dbc
VERSION ""

NS_ :

BS_:

BU_: Vector__XXX

BO_ 4096 TelemLeader_Center: 2 Vector__XXX
	SG_ Timestamp : 0|16@1+ (1,0) [0|65535] "" Vector__XXX
BA_ "VFrameFormat" BO_ 4096 "ExtendedCAN";

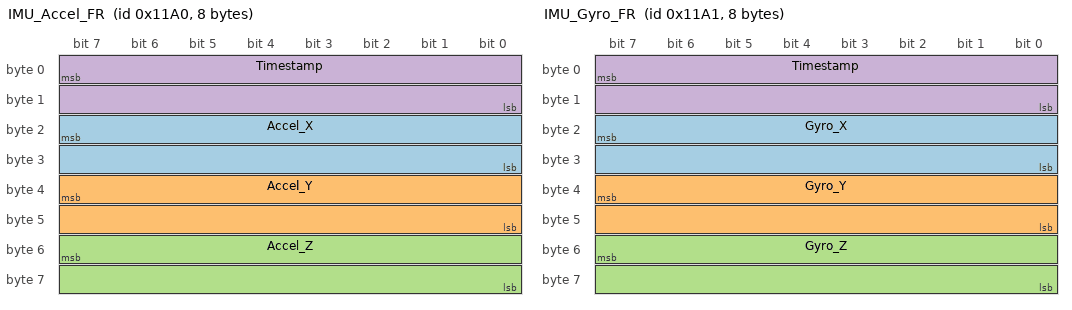
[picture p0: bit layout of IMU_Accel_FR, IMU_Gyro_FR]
BO_ 4512 IMU_Accel_FR: 8 Vector__XXX
	SG_ Accel_X : 23|16@0- (0.000122,0) [-3.997696|3.997574] "g" Vector__XXX
	SG_ Accel_Y : 39|16@0- (0.000122,0) [-3.997696|3.997574] "g" Vector__XXX
	SG_ Accel_Z : 55|16@0- (0.000122,0) [-3.997696|3.997574] "g" Vector__XXX
	SG_ Timestamp : 7|16@0+ (1,0) [0|65535] "" Vector__XXX
BA_ "VFrameFormat" BO_ 4512 "ExtendedCAN";

BO_ 4513 IMU_Gyro_FR: 8 Vector__XXX
	SG_ Gyro_X : 23|16@0- (0.00875,0) [-286.72|286.71125] "dps" Vector__XXX
	SG_ Gyro_Y : 39|16@0- (0.00875,0) [-286.72|286.71125] "dps" Vector__XXX
	SG_ Gyro_Z : 55|16@0- (0.00875,0) [-286.72|286.71125] "dps" Vector__XXX
	SG_ Timestamp : 7|16@0+ (1,0) [0|65535] "" Vector__XXX
BA_ "VFrameFormat" BO_ 4513 "ExtendedCAN";

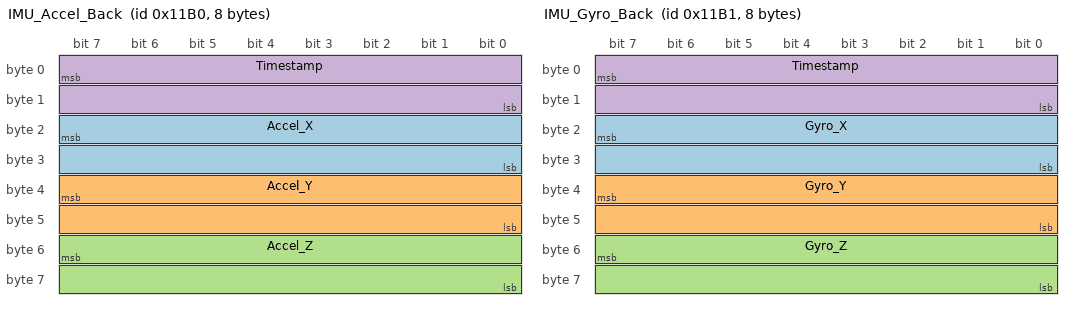
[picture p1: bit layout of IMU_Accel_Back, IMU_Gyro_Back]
BO_ 4528 IMU_Accel_Back: 8 Vector__XXX
	SG_ Accel_X : 23|16@0- (0.000122,0) [-3.997696|3.997574] "g" Vector__XXX
	SG_ Accel_Y : 39|16@0- (0.000122,0) [-3.997696|3.997574] "g" Vector__XXX
	SG_ Accel_Z : 55|16@0- (0.000122,0) [-3.997696|3.997574] "g" Vector__XXX
	SG_ Timestamp : 7|16@0+ (1,0) [0|65535] "" Vector__XXX
BA_ "VFrameFormat" BO_ 4528 "ExtendedCAN";

BO_ 4529 IMU_Gyro_Back: 8 Vector__XXX
	SG_ Gyro_X : 23|16@0- (0.00875,0) [-286.72|286.71125] "dps" Vector__XXX
	SG_ Gyro_Y : 39|16@0- (0.00875,0) [-286.72|286.71125] "dps" Vector__XXX
	SG_ Gyro_Z : 55|16@0- (0.00875,0) [-286.72|286.71125] "dps" Vector__XXX
	SG_ Timestamp : 7|16@0+ (1,0) [0|65535] "" Vector__XXX
BA_ "VFrameFormat" BO_ 4529 "ExtendedCAN";

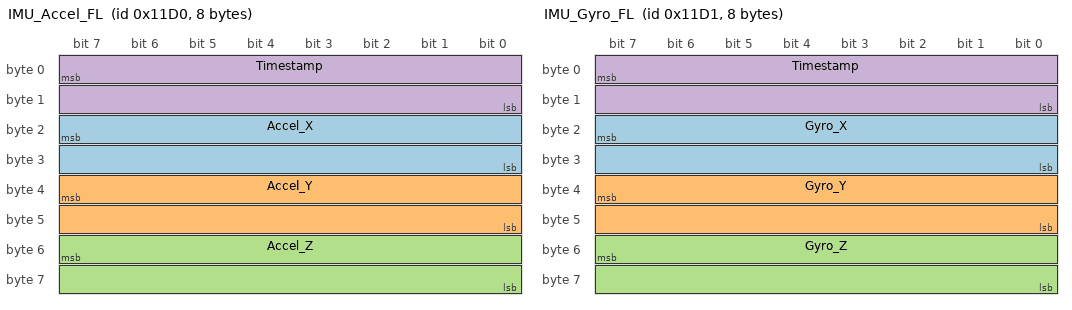
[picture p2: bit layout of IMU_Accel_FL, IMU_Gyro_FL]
BO_ 4560 IMU_Accel_FL: 8 Vector__XXX
	SG_ Accel_X : 23|16@0- (0.000122,0) [-3.997696|3.997574] "g" Vector__XXX
	SG_ Accel_Y : 39|16@0- (0.000122,0) [-3.997696|3.997574] "g" Vector__XXX
	SG_ Accel_Z : 55|16@0- (0.000122,0) [-3.997696|3.997574] "g" Vector__XXX
	SG_ Timestamp : 7|16@0+ (1,0) [0|65535] "" Vector__XXX
BA_ "VFrameFormat" BO_ 4560 "ExtendedCAN";

BO_ 4561 IMU_Gyro_FL: 8 Vector__XXX
	SG_ Gyro_X : 23|16@0- (0.00875,0) [-286.72|286.71125] "dps" Vector__XXX
	SG_ Gyro_Y : 39|16@0- (0.00875,0) [-286.72|286.71125] "dps" Vector__XXX
	SG_ Gyro_Z : 55|16@0- (0.00875,0) [-286.72|286.71125] "dps" Vector__XXX
	SG_ Timestamp : 7|16@0+ (1,0) [0|65535] "" Vector__XXX
BA_ "VFrameFormat" BO_ 4561 "ExtendedCAN";

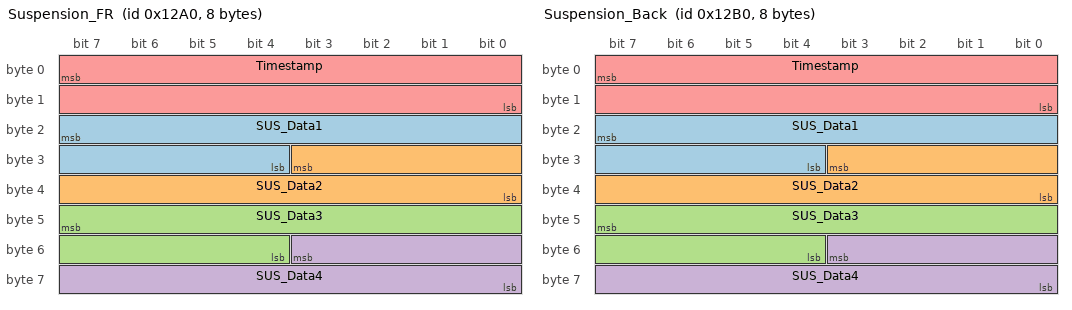
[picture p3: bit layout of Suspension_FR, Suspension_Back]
BO_ 4768 Suspension_FR: 8 Vector__XXX
	SG_ SUS_Data1 : 23|12@0+ (1,0) [0|4095] "" Vector__XXX
	SG_ SUS_Data2 : 27|12@0+ (1,0) [0|4095] "" Vector__XXX
	SG_ SUS_Data3 : 47|12@0+ (1,0) [0|4095] "" Vector__XXX
	SG_ SUS_Data4 : 51|12@0+ (1,0) [0|4095] "" Vector__XXX
	SG_ Timestamp : 7|16@0+ (1,0) [0|65535] "" Vector__XXX
BA_ "VFrameFormat" BO_ 4768 "ExtendedCAN";

BO_ 4784 Suspension_Back: 8 Vector__XXX
	SG_ SUS_Data1 : 23|12@0+ (1,0) [0|4095] "" Vector__XXX
	SG_ SUS_Data2 : 27|12@0+ (1,0) [0|4095] "" Vector__XXX
	SG_ SUS_Data3 : 47|12@0+ (1,0) [0|4095] "" Vector__XXX
	SG_ SUS_Data4 : 51|12@0+ (1,0) [0|4095] "" Vector__XXX
	SG_ Timestamp : 7|16@0+ (1,0) [0|65535] "" Vector__XXX
BA_ "VFrameFormat" BO_ 4784 "ExtendedCAN";

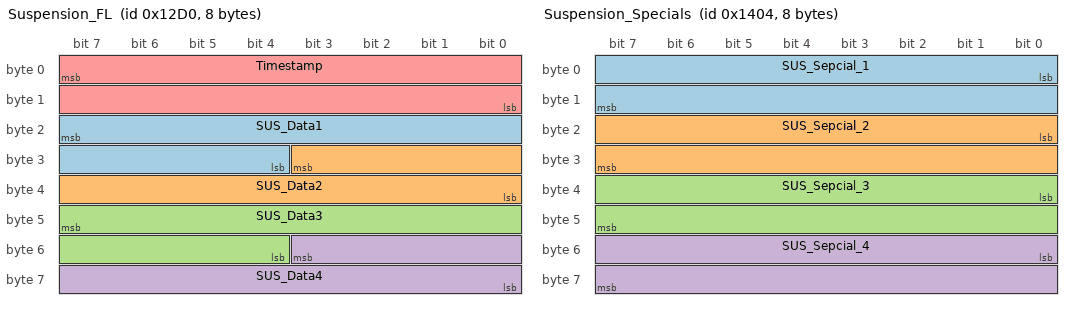
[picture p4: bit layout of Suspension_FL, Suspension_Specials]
BO_ 4816 Suspension_FL: 8 Vector__XXX
	SG_ SUS_Data1 : 23|12@0+ (1,0) [0|4095] "" Vector__XXX
	SG_ SUS_Data2 : 27|12@0+ (1,0) [0|4095] "" Vector__XXX
	SG_ SUS_Data3 : 47|12@0+ (1,0) [0|4095] "" Vector__XXX
	SG_ SUS_Data4 : 51|12@0+ (1,0) [0|4095] "" Vector__XXX
	SG_ Timestamp : 7|16@0+ (1,0) [0|65535] "" Vector__XXX
BA_ "VFrameFormat" BO_ 4816 "ExtendedCAN";

BO_ 5124 Suspension_Specials: 8 Vector__XXX
	SG_ SUS_Sepcial_1 : 0|16@1+ (1,0) [0|65535] "" Vector__XXX
	SG_ SUS_Sepcial_2 : 16|16@1+ (1,0) [0|65535] "" Vector__XXX
	SG_ SUS_Sepcial_3 : 32|16@1+ (1,0) [0|65535] "" Vector__XXX
	SG_ SUS_Sepcial_4 : 48|16@1+ (1,0) [0|65535] "" Vector__XXX
BA_ "VFrameFormat" BO_ 5124 "ExtendedCAN";

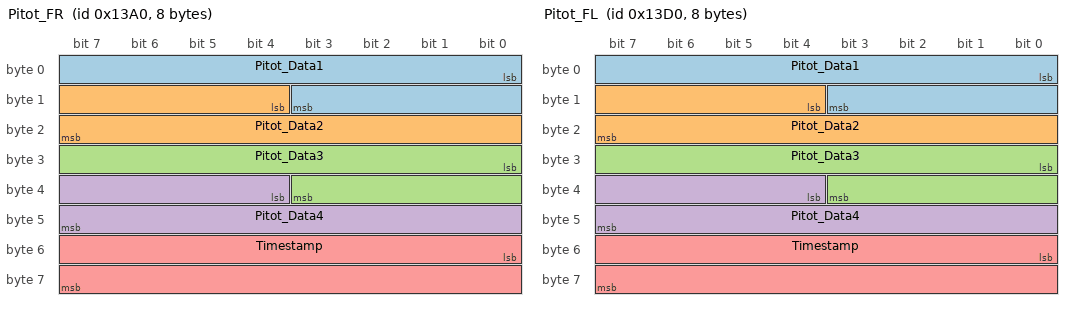
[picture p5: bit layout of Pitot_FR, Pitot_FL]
BO_ 5024 Pitot_FR: 8 Vector__XXX
	SG_ Pitot_Data1 : 0|12@1+ (1,0) [0|4095] "" Vector__XXX
	SG_ Pitot_Data2 : 12|12@1+ (1,0) [0|4095] "" Vector__XXX
	SG_ Pitot_Data3 : 24|12@1+ (1,0) [0|4095] "" Vector__XXX
	SG_ Pitot_Data4 : 36|12@1+ (1,0) [0|4095] "" Vector__XXX
	SG_ Timestamp : 48|16@1+ (1,0) [0|65535] "" Vector__XXX
BA_ "VFrameFormat" BO_ 5024 "ExtendedCAN";

BO_ 5072 Pitot_FL: 8 Vector__XXX
	SG_ Pitot_Data1 : 0|12@1+ (1,0) [0|4095] "" Vector__XXX
	SG_ Pitot_Data2 : 12|12@1+ (1,0) [0|4095] "" Vector__XXX
	SG_ Pitot_Data3 : 24|12@1+ (1,0) [0|4095] "" Vector__XXX
	SG_ Pitot_Data4 : 36|12@1+ (1,0) [0|4095] "" Vector__XXX
	SG_ Timestamp : 48|16@1+ (1,0) [0|65535] "" Vector__XXX
BA_ "VFrameFormat" BO_ 5072 "ExtendedCAN";

BO_ 5280 WheelRPM_FR: 8 Vector__XXX
	SG_ RPM : 0|16@1+ (0.01,0) [0|655.35] "rpm" Vector__XXX
	SG_ Timestamp : 16|16@1+ (1,0) [0|65535] "" Vector__XXX
BA_ "VFrameFormat" BO_ 5280 "ExtendedCAN";

BO_ 5328 WheelRPM_FL: 8 Vector__XXX
	SG_ RPM : 0|16@1+ (0.01,0) [0|655.35] "rpm" Vector__XXX
	SG_ Timestamp : 16|16@1+ (1,0) [0|65535] "" Vector__XXX
BA_ "VFrameFormat" BO_ 5328 "ExtendedCAN";

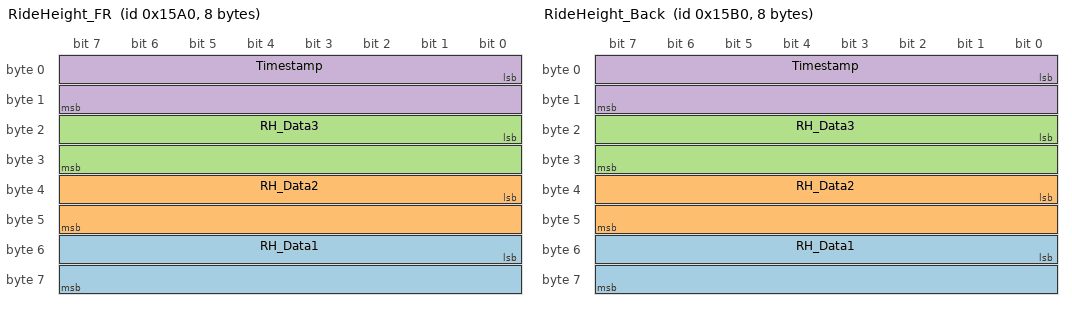
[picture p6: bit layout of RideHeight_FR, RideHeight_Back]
BO_ 5536 RideHeight_FR: 8 Vector__XXX
	SG_ RH_Data1 : 48|16@1+ (1,0) [0|65535] "" Vector__XXX
	SG_ RH_Data2 : 32|16@1+ (1,0) [0|65535] "" Vector__XXX
	SG_ RH_Data3 : 16|16@1+ (1,0) [0|65535] "" Vector__XXX
	SG_ Timestamp : 0|16@1+ (1,0) [0|65535] "" Vector__XXX
BA_ "VFrameFormat" BO_ 5536 "ExtendedCAN";

BO_ 5552 RideHeight_Back: 8 Vector__XXX
	SG_ RH_Data1 : 48|16@1+ (1,0) [0|65535] "" Vector__XXX
	SG_ RH_Data2 : 32|16@1+ (1,0) [0|65535] "" Vector__XXX
	SG_ RH_Data3 : 16|16@1+ (1,0) [0|65535] "" Vector__XXX
	SG_ Timestamp : 0|16@1+ (1,0) [0|65535] "" Vector__XXX
BA_ "VFrameFormat" BO_ 5552 "ExtendedCAN";

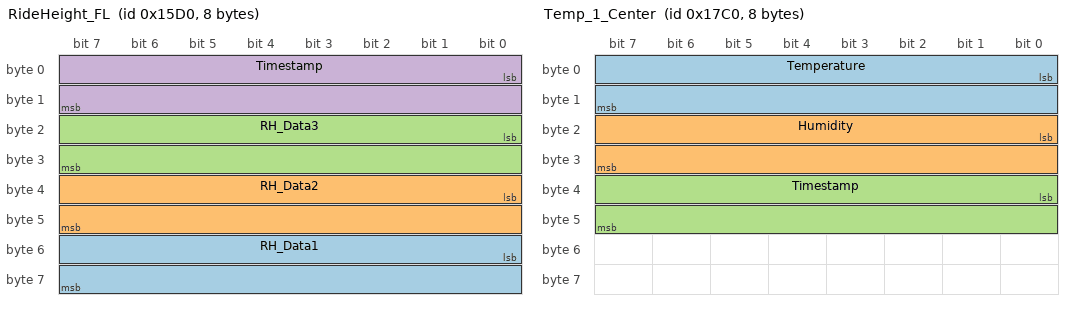
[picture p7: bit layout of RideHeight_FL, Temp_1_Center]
BO_ 5584 RideHeight_FL: 8 Vector__XXX
	SG_ RH_Data1 : 48|16@1+ (1,0) [0|65535] "" Vector__XXX
	SG_ RH_Data2 : 32|16@1+ (1,0) [0|65535] "" Vector__XXX
	SG_ RH_Data3 : 16|16@1+ (1,0) [0|65535] "" Vector__XXX
	SG_ Timestamp : 0|16@1+ (1,0) [0|65535] "" Vector__XXX
BA_ "VFrameFormat" BO_ 5584 "ExtendedCAN";

BO_ 6080 Temp_1_Center: 8 Vector__XXX
	SG_ Temperature : 0|16@1+ (1,0) [0|65535] "" Vector__XXX
	SG_ Humidity : 16|16@1+ (1,0) [0|65535] "" Vector__XXX
	SG_ Timestamp : 32|16@1+ (1,0) [0|65535] "" Vector__XXX
BA_ "VFrameFormat" BO_ 6080 "ExtendedCAN";

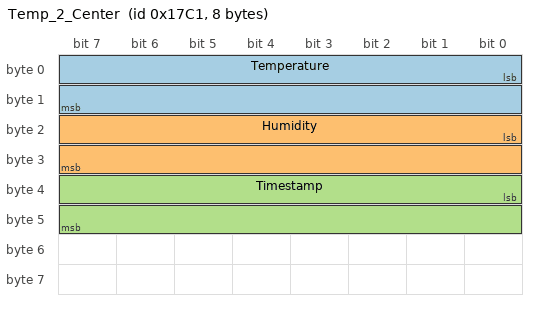
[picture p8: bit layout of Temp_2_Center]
BO_ 6081 Temp_2_Center: 8 Vector__XXX
	SG_ Temperature : 0|16@1+ (1,0) [0|65535] "" Vector__XXX
	SG_ Humidity : 16|16@1+ (1,0) [0|65535] "" Vector__XXX
	SG_ Timestamp : 32|16@1+ (1,0) [0|65535] "" Vector__XXX
BA_ "VFrameFormat" BO_ 6081 "ExtendedCAN";

BO_ 5888 GPS_Latitude: 4 Vector__XXX
	SG_ GPS_Latitude : 0|32@1+ (1,0) [0|4294967295] "" Vector__XXX
BA_ "VFrameFormat" BO_ 5888 "ExtendedCAN";

BO_ 5889 GPS_Longitude: 4 Vector__XXX
	SG_ GPS_Longitude : 0|32@1+ (1,0) [0|4294967295] "" Vector__XXX
BA_ "VFrameFormat" BO_ 5889 "ExtendedCAN";

BO_ 5890 GPS_Speed: 2 Vector__XXX
	SG_ GPS_Speed : 0|16@1+ (1,0) [0|65535] "" Vector__XXX
BA_ "VFrameFormat" BO_ 5890 "ExtendedCAN";

BO_ 5891 GPS_Status: 1 Vector__XXX
	SG_ GPS_Status : 0|8@1+ (1,0) [0|255] "" Vector__XXX
BA_ "VFrameFormat" BO_ 5891 "ExtendedCAN";

CM_ BO_ 4096 "Telem Leader Node";
CM_ SG_ 4096 Timestamp "Wheel-Based Vehicle Speed: Speed of the vehicle as calculated from wheel or tailshaft speed.";

BA_DEF_ BO_  "VFrameFormat" ENUM  "StandardCAN","ExtendedCAN","reserved","J1939PG";
BA_DEF_  "DatabaseVersion" STRING ;
BA_DEF_  "BusType" STRING ;
BA_DEF_  "ProtocolType" STRING ;
BA_DEF_  "DatabaseCompiler" STRING ;
BA_DEF_DEF_  "VFrameFormat" "J1939PG";
BA_DEF_DEF_  "DatabaseVersion" "DEMO PLUS";
BA_DEF_DEF_  "BusType" "";
BA_DEF_DEF_  "ProtocolType" "";
BA_DEF_DEF_  "DatabaseCompiler" "";
BA_ "BusType" "CAN";
BA_ "DatabaseCompiler" "CSS ELECTRONICS (WWW.CSSELECTRONICS.COM)";
BA_ "DatabaseVersion" "1.0.0";
